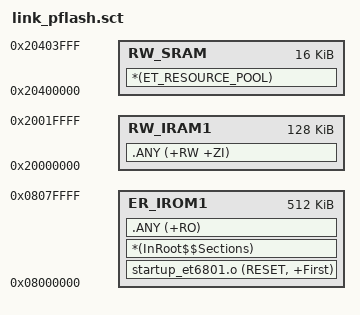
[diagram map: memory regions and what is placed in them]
LR_IROM1 0x08000000 0x00080000
{
    ER_IROM1 0x08000000 0x00080000
    {
        startup_et6801.o (RESET, +First)
        *(InRoot$$Sections)
        .ANY (+RO)
    }

    RW_SRAM 0x20400000 0x00004000
    {
        *(ET_RESOURCE_POOL)
    }

    RW_IRAM1 0x20000000 0x00020000
    {
        .ANY (+RW +ZI)
    }
}
